AUTOSAR XML (schema 4-0-3)
package /ComponentTypes
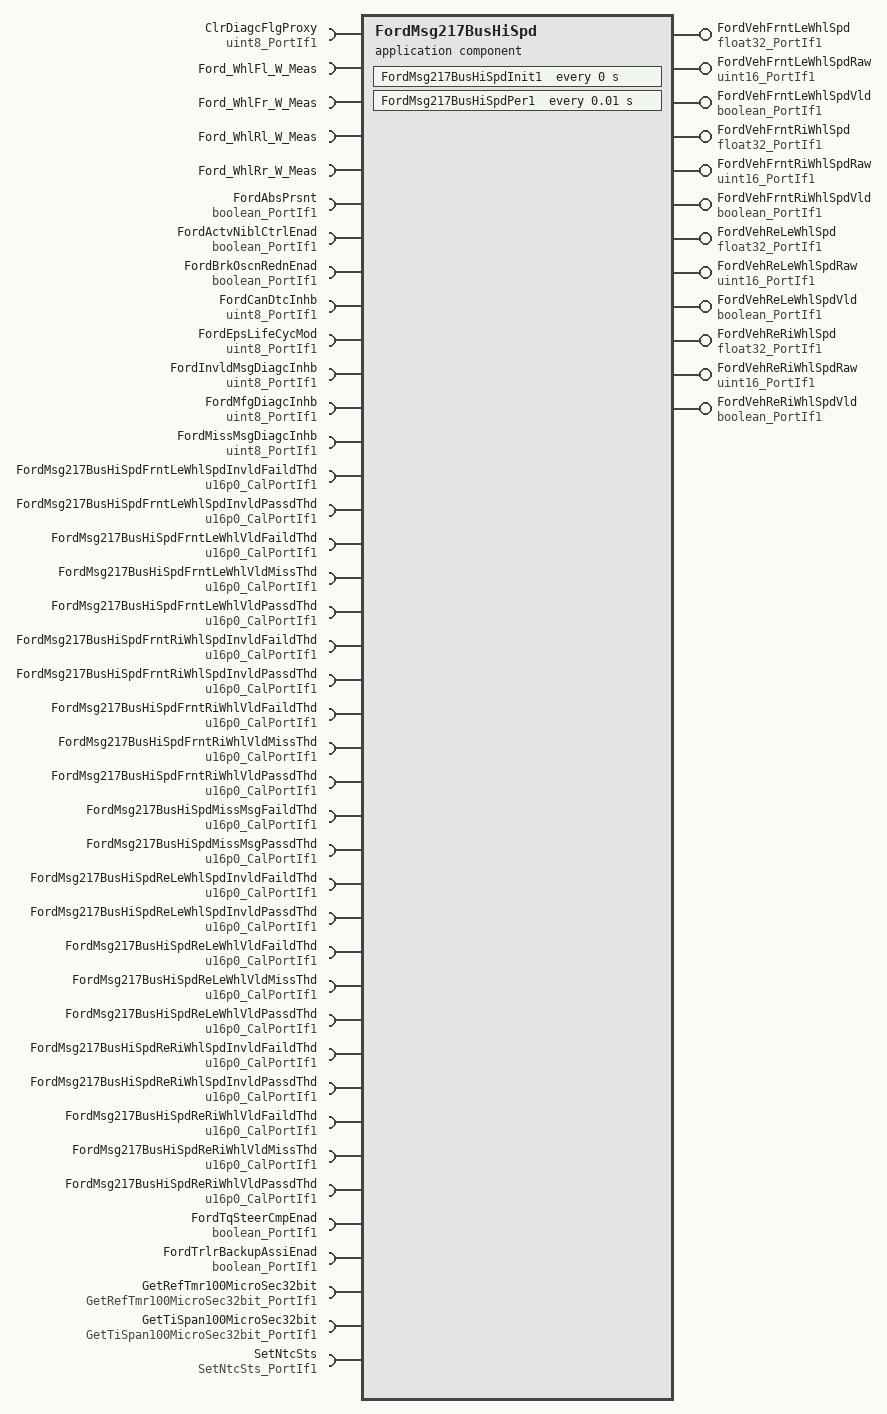
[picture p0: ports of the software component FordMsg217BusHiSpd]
  application sw component type FordMsg217BusHiSpd  # The purpose of the Ford Message 217 Bus High Speed function is to provide the Electric Power Steering system with signal values for vehicle speed, Active Nibble Control,TSC, Brake Oscillation Reduction, and Trailer Back Up Assist functions from CAN. The Ford Message 217Bus High Speed function will perform the missing message and signal invalid diagnostics as well as providea validity signal for the signal values and received message.
    12 x provide port:
      FordVehFrntLeWhlSpd: nonqueued-sender-com-spec{data-element=Val, init-value=0}, provided-interface=float32_PortIf1
      FordVehFrntLeWhlSpdRaw: nonqueued-sender-com-spec{data-element=Val, init-value=0}, provided-interface=uint16_PortIf1
      FordVehFrntLeWhlSpdVld: nonqueued-sender-com-spec{data-element=Logl, init-value=0}, provided-interface=boolean_PortIf1
      FordVehFrntRiWhlSpd: nonqueued-sender-com-spec{data-element=Val, init-value=0}, provided-interface=float32_PortIf1
      FordVehFrntRiWhlSpdRaw: nonqueued-sender-com-spec{data-element=Val, init-value=0}, provided-interface=uint16_PortIf1
      FordVehFrntRiWhlSpdVld: nonqueued-sender-com-spec{data-element=Logl, init-value=0}, provided-interface=boolean_PortIf1
      FordVehReLeWhlSpd: nonqueued-sender-com-spec{data-element=Val, init-value=0}, provided-interface=float32_PortIf1
      FordVehReLeWhlSpdRaw: nonqueued-sender-com-spec{data-element=Val, init-value=0}, provided-interface=uint16_PortIf1
      FordVehReLeWhlSpdVld: nonqueued-sender-com-spec{data-element=Logl, init-value=0}, provided-interface=boolean_PortIf1
      FordVehReRiWhlSpd: nonqueued-sender-com-spec{data-element=Val, init-value=0}, provided-interface=float32_PortIf1
      FordVehReRiWhlSpdRaw: nonqueued-sender-com-spec{data-element=Val, init-value=0}, provided-interface=uint16_PortIf1
      FordVehReRiWhlSpdVld: nonqueued-sender-com-spec{data-element=Logl, init-value=0}, provided-interface=boolean_PortIf1
    40 x require port:
      ClrDiagcFlgProxy: nonqueued-receiver-com-spec{data-element=Val, filter=data-filter-type=ALWAYS, init-value=0}, required-interface=uint8_PortIf1
      Ford_WhlFl_W_Meas: nonqueued-receiver-com-spec{data-element=Ford_WhlFl_W_Meas, filter=data-filter-type=ALWAYS, init-value=0}, required-interface=Ford_WhlFl_W_Meas
      Ford_WhlFr_W_Meas: nonqueued-receiver-com-spec{data-element=Ford_WhlFr_W_Meas, filter=data-filter-type=ALWAYS, init-value=0}, required-interface=Ford_WhlFr_W_Meas
      Ford_WhlRl_W_Meas: nonqueued-receiver-com-spec{data-element=Ford_WhlRl_W_Meas, filter=data-filter-type=ALWAYS, init-value=0}, required-interface=Ford_WhlRl_W_Meas
      Ford_WhlRr_W_Meas: nonqueued-receiver-com-spec{data-element=Ford_WhlRr_W_Meas, filter=data-filter-type=ALWAYS, init-value=0}, required-interface=Ford_WhlRr_W_Meas
      FordAbsPrsnt: nonqueued-receiver-com-spec{data-element=Logl, filter=data-filter-type=ALWAYS, init-value=0}, required-interface=boolean_PortIf1
      FordActvNiblCtrlEnad: nonqueued-receiver-com-spec{data-element=Logl, filter=data-filter-type=ALWAYS, init-value=0}, required-interface=boolean_PortIf1
      FordBrkOscnRednEnad: nonqueued-receiver-com-spec{data-element=Logl, filter=data-filter-type=ALWAYS, init-value=0}, required-interface=boolean_PortIf1
      FordCanDtcInhb: nonqueued-receiver-com-spec{data-element=Val, filter=data-filter-type=ALWAYS, init-value=1}, required-interface=uint8_PortIf1
      FordEpsLifeCycMod: nonqueued-receiver-com-spec{data-element=Val, filter=data-filter-type=ALWAYS, init-value=0}, required-interface=uint8_PortIf1
      FordInvldMsgDiagcInhb: nonqueued-receiver-com-spec{data-element=Val, filter=data-filter-type=ALWAYS, init-value=0}, required-interface=uint8_PortIf1
      FordMfgDiagcInhb: nonqueued-receiver-com-spec{data-element=Val, filter=data-filter-type=ALWAYS, init-value=0}, required-interface=uint8_PortIf1
      FordMissMsgDiagcInhb: nonqueued-receiver-com-spec{data-element=Val, filter=data-filter-type=ALWAYS, init-value=0}, required-interface=uint8_PortIf1
      FordMsg217BusHiSpdFrntLeWhlSpdInvldFaildThd: parameter-require-com-spec{init-value=0, parameter=Val}, required-interface=u16p0_CalPortIf1
      FordMsg217BusHiSpdFrntLeWhlSpdInvldPassdThd: parameter-require-com-spec{init-value=0, parameter=Val}, required-interface=u16p0_CalPortIf1
      FordMsg217BusHiSpdFrntLeWhlVldFaildThd: parameter-require-com-spec{init-value=0, parameter=Val}, required-interface=u16p0_CalPortIf1
      FordMsg217BusHiSpdFrntLeWhlVldMissThd: parameter-require-com-spec{init-value=100, parameter=Val}, required-interface=u16p0_CalPortIf1
      FordMsg217BusHiSpdFrntLeWhlVldPassdThd: parameter-require-com-spec{init-value=0, parameter=Val}, required-interface=u16p0_CalPortIf1
      FordMsg217BusHiSpdFrntRiWhlSpdInvldFaildThd: parameter-require-com-spec{init-value=0, parameter=Val}, required-interface=u16p0_CalPortIf1
      FordMsg217BusHiSpdFrntRiWhlSpdInvldPassdThd: parameter-require-com-spec{init-value=0, parameter=Val}, required-interface=u16p0_CalPortIf1
      FordMsg217BusHiSpdFrntRiWhlVldFaildThd: parameter-require-com-spec{init-value=0, parameter=Val}, required-interface=u16p0_CalPortIf1
      FordMsg217BusHiSpdFrntRiWhlVldMissThd: parameter-require-com-spec{init-value=100, parameter=Val}, required-interface=u16p0_CalPortIf1
      FordMsg217BusHiSpdFrntRiWhlVldPassdThd: parameter-require-com-spec{init-value=0, parameter=Val}, required-interface=u16p0_CalPortIf1
      FordMsg217BusHiSpdMissMsgFaildThd: parameter-require-com-spec{init-value=100, parameter=Val}, required-interface=u16p0_CalPortIf1
      FordMsg217BusHiSpdMissMsgPassdThd: parameter-require-com-spec{init-value=0, parameter=Val}, required-interface=u16p0_CalPortIf1
      FordMsg217BusHiSpdReLeWhlSpdInvldFaildThd: parameter-require-com-spec{init-value=0, parameter=Val}, required-interface=u16p0_CalPortIf1
      FordMsg217BusHiSpdReLeWhlSpdInvldPassdThd: parameter-require-com-spec{init-value=0, parameter=Val}, required-interface=u16p0_CalPortIf1
      FordMsg217BusHiSpdReLeWhlVldFaildThd: parameter-require-com-spec{init-value=0, parameter=Val}, required-interface=u16p0_CalPortIf1
      FordMsg217BusHiSpdReLeWhlVldMissThd: parameter-require-com-spec{init-value=100, parameter=Val}, required-interface=u16p0_CalPortIf1
      FordMsg217BusHiSpdReLeWhlVldPassdThd: parameter-require-com-spec{init-value=0, parameter=Val}, required-interface=u16p0_CalPortIf1
      FordMsg217BusHiSpdReRiWhlSpdInvldFaildThd: parameter-require-com-spec{init-value=0, parameter=Val}, required-interface=u16p0_CalPortIf1
      FordMsg217BusHiSpdReRiWhlSpdInvldPassdThd: parameter-require-com-spec{init-value=0, parameter=Val}, required-interface=u16p0_CalPortIf1
      FordMsg217BusHiSpdReRiWhlVldFaildThd: parameter-require-com-spec{init-value=0, parameter=Val}, required-interface=u16p0_CalPortIf1
      FordMsg217BusHiSpdReRiWhlVldMissThd: parameter-require-com-spec{init-value=100, parameter=Val}, required-interface=u16p0_CalPortIf1
      FordMsg217BusHiSpdReRiWhlVldPassdThd: parameter-require-com-spec{init-value=0, parameter=Val}, required-interface=u16p0_CalPortIf1
      FordTqSteerCmpEnad: nonqueued-receiver-com-spec{data-element=Logl, filter=data-filter-type=ALWAYS, init-value=0}, required-interface=boolean_PortIf1
      FordTrlrBackupAssiEnad: nonqueued-receiver-com-spec{data-element=Logl, filter=data-filter-type=ALWAYS, init-value=0}, required-interface=boolean_PortIf1
      GetRefTmr100MicroSec32bit: client-com-spec=Oper, required-interface=GetRefTmr100MicroSec32bit_PortIf1  # It captures simulation time fromthe SimnTi value obtained at root layer of model and gives the RefTmr.
      GetTiSpan100MicroSec32bit: client-com-spec=Oper, required-interface=GetTiSpan100MicroSec32bit_PortIf1  # It Captures simulation time fromSimnTi value, handles counter wrapping, and subtracts RefTmr, provides the TiSpan.
      SetNtcSts: client-com-spec=Oper, required-interface=SetNtcSts_PortIf1  # Returns the NTC Qualifier status.
    behavior FordMsg217BusHiSpd_InternalBehavior
      ar-typed-per-instance-memorys:
        37 x data, all with sw-calibration-access=READ-ONLY:
          ClrDiagcFlgProxyPrev: type=uint8
          FordVehFrntLeWhlSpdInvldFaildRefTi: type=uint32
          FordVehFrntLeWhlSpdInvldPassdRefTi: type=uint32
          FordVehFrntLeWhlSpdPrev: type=float32
          FordVehFrntLeWhlSpdRawPrev: type=uint16
          FordVehFrntLeWhlSpdVldFaildRefTi: type=uint32
          FordVehFrntLeWhlSpdVldMissRefTi: type=uint32
          FordVehFrntLeWhlSpdVldPassdRefTi: type=uint32
          FordVehFrntLeWhlSpdVldPrev: type=boolean
          FordVehFrntRiWhlSpdInvldFaildRefTi: type=uint32
          FordVehFrntRiWhlSpdInvldPassdRefTi: type=uint32
          FordVehFrntRiWhlSpdPrev: type=float32
          FordVehFrntRiWhlSpdRawPrev: type=uint16
          FordVehFrntRiWhlSpdVldFaildRefTi: type=uint32
          FordVehFrntRiWhlSpdVldMissRefTi: type=uint32
          FordVehFrntRiWhlSpdVldPassdRefTi: type=uint32
          FordVehFrntRiWhlSpdVldPrev: type=boolean
          FordVehMsg217Miss: type=boolean
          FordVehMsg217Rxd: type=boolean
          FordVehReLeWhlSpdInvldFaildRefTi: type=uint32
          FordVehReLeWhlSpdInvldPassdRefTi: type=uint32
          FordVehReLeWhlSpdPrev: type=float32
          FordVehReLeWhlSpdRawPrev: type=uint16
          FordVehReLeWhlSpdVldFaildRefTi: type=uint32
          FordVehReLeWhlSpdVldMissRefTi: type=uint32
          FordVehReLeWhlSpdVldPassdRefTi: type=uint32
          FordVehReLeWhlSpdVldPrev: type=boolean
          FordVehReRiWhlSpdInvldFaildRefTi: type=uint32
          FordVehReRiWhlSpdInvldPassdRefTi: type=uint32
          FordVehReRiWhlSpdPrev: type=float32
          FordVehReRiWhlSpdRawPrev: type=uint16
          FordVehReRiWhlSpdVldFaildRefTi: type=uint32
          FordVehReRiWhlSpdVldMissRefTi: type=uint32
          FordVehReRiWhlSpdVldPassdRefTi: type=uint32
          FordVehReRiWhlSpdVldPrev: type=boolean
          MissMsgFaildRefTi: type=uint32
          MissMsgPassdRefTi: type=uint32
      timing event FordMsg217BusHiSpd_InitEvent: start-on-event=FordMsg217BusHiSpdInit1, period=0
      timing event TMT_FordMsg217BusHiSpdPer1: start-on-event=FordMsg217BusHiSpdPer1, period=0.01
      port-api-options:
        enable-take-address=false, indirect-api=false, port=ClrDiagcFlgProxy
        enable-take-address=false, indirect-api=false, port=Ford_WhlFl_W_Meas
        enable-take-address=false, indirect-api=false, port=Ford_WhlFr_W_Meas
        enable-take-address=false, indirect-api=false, port=Ford_WhlRl_W_Meas
        enable-take-address=false, indirect-api=false, port=Ford_WhlRr_W_Meas
        enable-take-address=false, indirect-api=false, port=FordAbsPrsnt
        enable-take-address=false, indirect-api=false, port=FordActvNiblCtrlEnad
        enable-take-address=false, indirect-api=false, port=FordBrkOscnRednEnad
        enable-take-address=false, indirect-api=false, port=FordCanDtcInhb
        enable-take-address=false, indirect-api=false, port=FordEpsLifeCycMod
        enable-take-address=false, indirect-api=false, port=FordInvldMsgDiagcInhb
        enable-take-address=false, indirect-api=false, port=FordMfgDiagcInhb
        enable-take-address=false, indirect-api=false, port=FordMissMsgDiagcInhb
        enable-take-address=false, indirect-api=false, port=FordMsg217BusHiSpdFrntLeWhlSpdInvldFaildThd
        enable-take-address=false, indirect-api=false, port=FordMsg217BusHiSpdFrntLeWhlSpdInvldPassdThd
        enable-take-address=false, indirect-api=false, port=FordMsg217BusHiSpdFrntLeWhlVldFaildThd
        enable-take-address=false, indirect-api=false, port=FordMsg217BusHiSpdFrntLeWhlVldMissThd
        enable-take-address=false, indirect-api=false, port=FordMsg217BusHiSpdFrntLeWhlVldPassdThd
        enable-take-address=false, indirect-api=false, port=FordMsg217BusHiSpdFrntRiWhlSpdInvldFaildThd
        enable-take-address=false, indirect-api=false, port=FordMsg217BusHiSpdFrntRiWhlSpdInvldPassdThd
        enable-take-address=false, indirect-api=false, port=FordMsg217BusHiSpdFrntRiWhlVldFaildThd
        enable-take-address=false, indirect-api=false, port=FordMsg217BusHiSpdFrntRiWhlVldMissThd
        enable-take-address=false, indirect-api=false, port=FordMsg217BusHiSpdFrntRiWhlVldPassdThd
        enable-take-address=false, indirect-api=false, port=FordMsg217BusHiSpdMissMsgFaildThd
        enable-take-address=false, indirect-api=false, port=FordMsg217BusHiSpdMissMsgPassdThd
        enable-take-address=false, indirect-api=false, port=FordMsg217BusHiSpdReLeWhlSpdInvldFaildThd
        enable-take-address=false, indirect-api=false, port=FordMsg217BusHiSpdReLeWhlSpdInvldPassdThd
        enable-take-address=false, indirect-api=false, port=FordMsg217BusHiSpdReLeWhlVldFaildThd
        enable-take-address=false, indirect-api=false, port=FordMsg217BusHiSpdReLeWhlVldMissThd
      runnable FordMsg217BusHiSpdInit1  # Initialization Runnable
        sync call SC_GetRefTmr100MicroSec32bit_Oper: operation=GetRefTmr100MicroSec32bit.Oper, timeout=0
      runnable FordMsg217BusHiSpdPer1  # Periodic Runnable at 10 millisec
        data-receive-point-by-arguments:
          15 x access:
            REC_ClrDiagcFlgProxy_Val: accessed-variable=ClrDiagcFlgProxy.Val
            REC_Ford_WhlFl_W_Meas_Ford_WhlFl_W_Meas: accessed-variable=Ford_WhlFl_W_Meas.Ford_WhlFl_W_Meas
            REC_Ford_WhlFr_W_Meas_Ford_WhlFr_W_Meas: accessed-variable=Ford_WhlFr_W_Meas.Ford_WhlFr_W_Meas
            REC_Ford_WhlRl_W_Meas_Ford_WhlRl_W_Meas: accessed-variable=Ford_WhlRl_W_Meas.Ford_WhlRl_W_Meas
            REC_Ford_WhlRr_W_Meas_Ford_WhlRr_W_Meas: accessed-variable=Ford_WhlRr_W_Meas.Ford_WhlRr_W_Meas
            REC_FordAbsPrsnt_Logl: accessed-variable=FordAbsPrsnt.Logl
            REC_FordActvNiblCtrlEnad_Logl: accessed-variable=FordActvNiblCtrlEnad.Logl
            REC_FordBrkOscnRednEnad_Logl: accessed-variable=FordBrkOscnRednEnad.Logl
            REC_FordCanDtcInhb_Val: accessed-variable=FordCanDtcInhb.Val
            REC_FordEpsLifeCycMod_Val: accessed-variable=FordEpsLifeCycMod.Val
            REC_FordInvldMsgDiagcInhb_Val: accessed-variable=FordInvldMsgDiagcInhb.Val
            REC_FordMfgDiagcInhb_Val: accessed-variable=FordMfgDiagcInhb.Val
            REC_FordMissMsgDiagcInhb_Val: accessed-variable=FordMissMsgDiagcInhb.Val
            REC_FordTqSteerCmpEnad_Logl: accessed-variable=FordTqSteerCmpEnad.Logl
            REC_FordTrlrBackupAssiEnad_Logl: accessed-variable=FordTrlrBackupAssiEnad.Logl
        data-send-points:
          12 x access:
            SEND_FordVehFrntLeWhlSpd_Val: accessed-variable=FordVehFrntLeWhlSpd.Val
            SEND_FordVehFrntLeWhlSpdRaw_Val: accessed-variable=FordVehFrntLeWhlSpdRaw.Val
            SEND_FordVehFrntLeWhlSpdVld_Logl: accessed-variable=FordVehFrntLeWhlSpdVld.Logl
            SEND_FordVehFrntRiWhlSpd_Val: accessed-variable=FordVehFrntRiWhlSpd.Val
            SEND_FordVehFrntRiWhlSpdRaw_Val: accessed-variable=FordVehFrntRiWhlSpdRaw.Val
            SEND_FordVehFrntRiWhlSpdVld_Logl: accessed-variable=FordVehFrntRiWhlSpdVld.Logl
            SEND_FordVehReLeWhlSpd_Val: accessed-variable=FordVehReLeWhlSpd.Val
            SEND_FordVehReLeWhlSpdRaw_Val: accessed-variable=FordVehReLeWhlSpdRaw.Val
            SEND_FordVehReLeWhlSpdVld_Logl: accessed-variable=FordVehReLeWhlSpdVld.Logl
            SEND_FordVehReRiWhlSpd_Val: accessed-variable=FordVehReRiWhlSpd.Val
            SEND_FordVehReRiWhlSpdRaw_Val: accessed-variable=FordVehReRiWhlSpdRaw.Val
            SEND_FordVehReRiWhlSpdVld_Logl: accessed-variable=FordVehReRiWhlSpdVld.Logl
        sync call SC_GetRefTmr100MicroSec32bit_Oper: operation=GetRefTmr100MicroSec32bit.Oper, timeout=0
        sync call SC_GetTiSpan100MicroSec32bit_Oper: operation=GetTiSpan100MicroSec32bit.Oper, timeout=0
        sync call SC_SetNtcSts_Oper: operation=SetNtcSts.Oper, timeout=0
  swc implementation FordMsg217BusHiSpd_Implementation: behavior=FordMsg217BusHiSpd_InternalBehavior
    code-descriptors:
      code Default: artifact-descriptors=autosar-engineering-object={short-label=Default, category=SWSRC}
